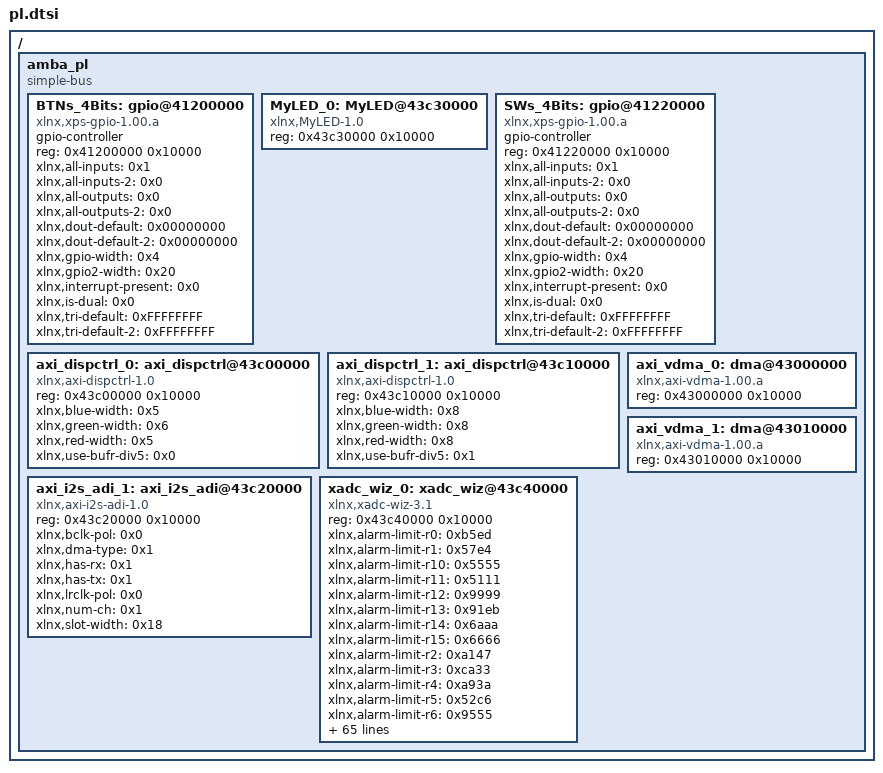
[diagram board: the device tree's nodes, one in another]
/*
 * CAUTION: This file is automatically generated by Xilinx.
 * Version: HSI 
 * Today is: Fri Sep 18 20:50:50 2015
*/


/ {
	amba_pl: amba_pl {
		#address-cells = <1>;
		#size-cells = <1>;
		compatible = "simple-bus";
		ranges ;
		BTNs_4Bits: gpio@41200000 {
			#gpio-cells = <2>;
			compatible = "xlnx,xps-gpio-1.00.a";
			gpio-controller ;
			reg = <0x41200000 0x10000>;
			xlnx,all-inputs = <0x1>;
			xlnx,all-inputs-2 = <0x0>;
			xlnx,all-outputs = <0x0>;
			xlnx,all-outputs-2 = <0x0>;
			xlnx,dout-default = <0x00000000>;
			xlnx,dout-default-2 = <0x00000000>;
			xlnx,gpio-width = <0x4>;
			xlnx,gpio2-width = <0x20>;
			xlnx,interrupt-present = <0x0>;
			xlnx,is-dual = <0x0>;
			xlnx,tri-default = <0xFFFFFFFF>;
			xlnx,tri-default-2 = <0xFFFFFFFF>;
		};
		MyLED_0: MyLED@43c30000 {
			compatible = "xlnx,MyLED-1.0";
			reg = <0x43c30000 0x10000>;
		};
		SWs_4Bits: gpio@41220000 {
			#gpio-cells = <2>;
			compatible = "xlnx,xps-gpio-1.00.a";
			gpio-controller ;
			reg = <0x41220000 0x10000>;
			xlnx,all-inputs = <0x1>;
			xlnx,all-inputs-2 = <0x0>;
			xlnx,all-outputs = <0x0>;
			xlnx,all-outputs-2 = <0x0>;
			xlnx,dout-default = <0x00000000>;
			xlnx,dout-default-2 = <0x00000000>;
			xlnx,gpio-width = <0x4>;
			xlnx,gpio2-width = <0x20>;
			xlnx,interrupt-present = <0x0>;
			xlnx,is-dual = <0x0>;
			xlnx,tri-default = <0xFFFFFFFF>;
			xlnx,tri-default-2 = <0xFFFFFFFF>;
		};
		axi_dispctrl_0: axi_dispctrl@43c00000 {
			compatible = "xlnx,axi-dispctrl-1.0";
			reg = <0x43c00000 0x10000>;
			xlnx,blue-width = <0x5>;
			xlnx,green-width = <0x6>;
			xlnx,red-width = <0x5>;
			xlnx,use-bufr-div5 = <0x0>;
		};
		axi_dispctrl_1: axi_dispctrl@43c10000 {
			compatible = "xlnx,axi-dispctrl-1.0";
			reg = <0x43c10000 0x10000>;
			xlnx,blue-width = <0x8>;
			xlnx,green-width = <0x8>;
			xlnx,red-width = <0x8>;
			xlnx,use-bufr-div5 = <0x1>;
		};
		axi_i2s_adi_1: axi_i2s_adi@43c20000 {
			compatible = "xlnx,axi-i2s-adi-1.0";
			reg = <0x43c20000 0x10000>;
			xlnx,bclk-pol = <0x0>;
			xlnx,dma-type = <0x1>;
			xlnx,has-rx = <0x1>;
			xlnx,has-tx = <0x1>;
			xlnx,lrclk-pol = <0x0>;
			xlnx,num-ch = <0x1>;
			xlnx,slot-width = <0x18>;
		};
		axi_vdma_0: dma@43000000 {
			#dma-cells = <1>;
			compatible = "xlnx,axi-vdma-1.00.a";
			reg = <0x43000000 0x10000>;
		};
		axi_vdma_1: dma@43010000 {
			#dma-cells = <1>;
			compatible = "xlnx,axi-vdma-1.00.a";
			reg = <0x43010000 0x10000>;
		};
		xadc_wiz_0: xadc_wiz@43c40000 {
			compatible = "xlnx,xadc-wiz-3.1";
			reg = <0x43c40000 0x10000>;
			xlnx,alarm-limit-r0 = <0xb5ed>;
			xlnx,alarm-limit-r1 = <0x57e4>;
			xlnx,alarm-limit-r10 = <0x5555>;
			xlnx,alarm-limit-r11 = <0x5111>;
			xlnx,alarm-limit-r12 = <0x9999>;
			xlnx,alarm-limit-r13 = <0x91eb>;
			xlnx,alarm-limit-r14 = <0x6aaa>;
			xlnx,alarm-limit-r15 = <0x6666>;
			xlnx,alarm-limit-r2 = <0xa147>;
			xlnx,alarm-limit-r3 = <0xca33>;
			xlnx,alarm-limit-r4 = <0xa93a>;
			xlnx,alarm-limit-r5 = <0x52c6>;
			xlnx,alarm-limit-r6 = <0x9555>;
			xlnx,alarm-limit-r7 = <0xae4e>;
			xlnx,alarm-limit-r8 = <0x5999>;
			xlnx,alarm-limit-r9 = <0x5111>;
			xlnx,configuration-r0 = <0x0>;
			xlnx,configuration-r1 = <0x3100>;
			xlnx,configuration-r2 = <0x400>;
			xlnx,dclk-frequency = <0x64>;
			xlnx,external-mux-channel = "VP_VN";
			xlnx,external-muxaddr-enable = <0x0>;
			xlnx,fifo-depth = <0x7>;
			xlnx,has-axi = <0x1>;
			xlnx,has-axi4stream = <0x0>;
			xlnx,has-busy = <0x1>;
			xlnx,has-channel = <0x1>;
			xlnx,has-convst = <0x0>;
			xlnx,has-convstclk = <0x0>;
			xlnx,has-dclk = <0x1>;
			xlnx,has-drp = <0x0>;
			xlnx,has-eoc = <0x1>;
			xlnx,has-eos = <0x1>;
			xlnx,has-external-mux = <0x0>;
			xlnx,has-jtagbusy = <0x0>;
			xlnx,has-jtaglocked = <0x0>;
			xlnx,has-jtagmodified = <0x0>;
			xlnx,has-ot-alarm = <0x1>;
			xlnx,has-reset = <0x0>;
			xlnx,has-temp-bus = <0x0>;
			xlnx,has-user-temp-alarm = <0x1>;
			xlnx,has-vbram-alarm = <0x0>;
			xlnx,has-vccaux-alarm = <0x1>;
			xlnx,has-vccddro-alarm = <0x1>;
			xlnx,has-vccint-alarm = <0x1>;
			xlnx,has-vccpaux-alarm = <0x1>;
			xlnx,has-vccpint-alarm = <0x1>;
			xlnx,has-vn = <0x1>;
			xlnx,has-vp = <0x1>;
			xlnx,include-intr = <0x1>;
			xlnx,sampling-rate = "961538.4615384615";
			xlnx,sequence-r0 = <0x100>;
			xlnx,sequence-r1 = <0x0>;
			xlnx,sequence-r2 = <0x0>;
			xlnx,sequence-r3 = <0x0>;
			xlnx,sequence-r4 = <0x0>;
			xlnx,sequence-r5 = <0x0>;
			xlnx,sequence-r6 = <0x0>;
			xlnx,sequence-r7 = <0x0>;
			xlnx,sim-file-name = "design";
			xlnx,sim-file-rel-path = "./";
			xlnx,sim-file-sel = "Default";
			xlnx,vaux0 = <0x0>;
			xlnx,vaux1 = <0x0>;
			xlnx,vaux10 = <0x0>;
			xlnx,vaux11 = <0x0>;
			xlnx,vaux12 = <0x0>;
			xlnx,vaux13 = <0x0>;
			xlnx,vaux14 = <0x0>;
			xlnx,vaux15 = <0x0>;
			xlnx,vaux2 = <0x0>;
			xlnx,vaux3 = <0x0>;
			xlnx,vaux4 = <0x0>;
			xlnx,vaux5 = <0x0>;
			xlnx,vaux6 = <0x0>;
			xlnx,vaux7 = <0x0>;
			xlnx,vaux8 = <0x0>;
			xlnx,vaux9 = <0x0>;
		};
	};
};
